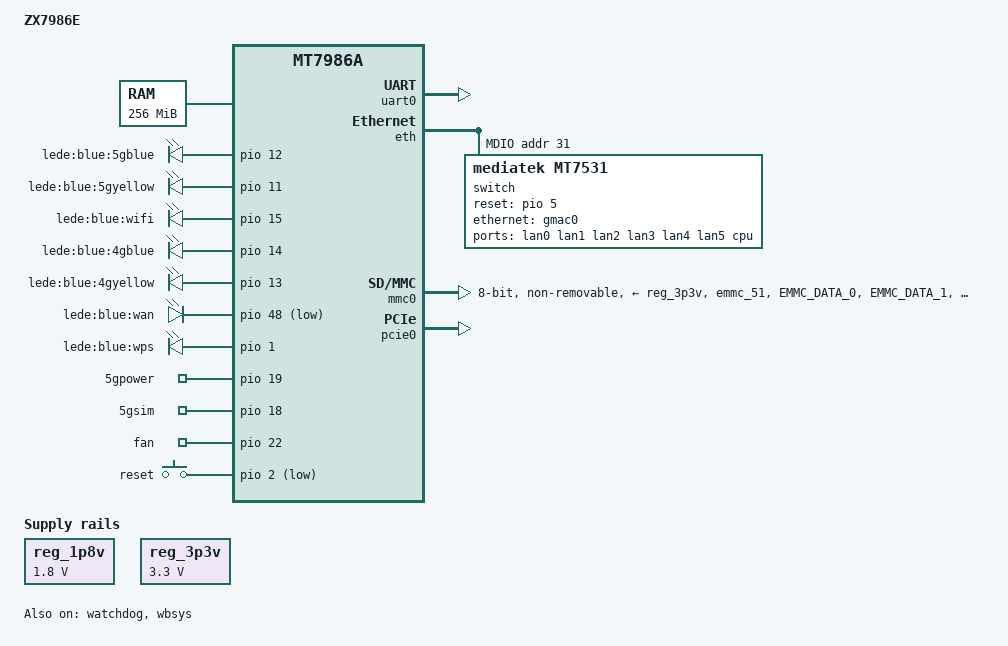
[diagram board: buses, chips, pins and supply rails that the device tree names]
/dts-v1/;
#include "mt7986a.dtsi"
#include "mt7986a-pinctrl.dtsi"
#include <dt-bindings/input/input.h>

/ {
	model = "ZX7986E";
	compatible = "ZX7986E";
	chosen {
		bootargs = "console=ttyS0,115200n1 loglevel=8  \
				earlycon=uart8250,mmio32,0x11002000 \
				root=PARTLABEL=rootfs rootwait rootfstype=squashfs,f2fs";
	};

	memory {
		reg = <0 0x40000000 0 0x10000000>;
	};

	gpio-leds {
		compatible = "gpio-leds";

		5gblue {
			label = "lede:blue:5gblue";
			gpios = <&pio 12 0>;
			linux,default-trigger = "none";
			default-state = "off";
		};

		5gyellow {
			label = "lede:blue:5gyellow";
			gpios = <&pio 11 0>;
			linux,default-trigger = "none";
			default-state = "off";
		};

		wifi {
			label = "lede:blue:wifi";
			gpios = <&pio 15 0>;
			linux,default-trigger = "none";
			default-state = "off";
		};

		4gblue {
			label = "lede:blue:4gblue";
			gpios = <&pio 14 0>;
			linux,default-trigger = "none";
			default-state = "off";
		};

		4gyellow {
			label = "lede:blue:4gyellow";
			gpios = <&pio 13 0>;
			linux,default-trigger = "none";
			default-state = "off";
		};

		wan {
			label = "lede:blue:wan";
			gpios = <&pio 48 1>;
			linux,default-trigger = "none";
			default-state = "off";
		};

		wps {
			label = "lede:blue:wps";
			gpios = <&pio 1 0>;
			linux,default-trigger = "none";
			default-state = "off";
		};
	};

	gpio-export {
		compatible = "gpio-export";
		5gpower {
			gpio-export,name = "5gpower";
			gpio-export,output = <0>; // OUT_INIT_LOW
			gpios = <&pio 19 0>;    // GPIO 19, ACTIVE_LOW
		};

		5gsim {
			gpio-export,name = "5gsim";
			gpio-export,output = <1>; // OUT_INIT_LOW
			gpios = <&pio 18 0>;    // GPIO 18, ACTIVE_LOW
		};

		fan {
			gpio-export,name = "fan";
			gpio-export,output = <1>; // OUT_INIT_LOW
			gpios = <&pio 22 0>;    // GPIO 22, ACTIVE_LOW
		};
	};

	gpio-keys {
		compatible = "gpio-keys";
		#address-cells = <1>;
		#size-cells = <0>;
		poll-interval = <20>;

		reset {
			label = "reset";
			gpios = <&pio 2 1>;
			linux,code = <KEY_RESTART>;
		};
	};

	reg_1p8v: regulator-1p8v {
		compatible = "regulator-fixed";
		regulator-name = "fixed-1.8V";
		regulator-min-microvolt = <1800000>;
		regulator-max-microvolt = <1800000>;
		regulator-boot-on;
		regulator-always-on;
	};

	reg_3p3v: regulator-3p3v {
		compatible = "regulator-fixed";
		regulator-name = "fixed-3.3V";
		regulator-min-microvolt = <3300000>;
		regulator-max-microvolt = <3300000>;
		regulator-boot-on;
		regulator-always-on;
	};

};

/*&pwm {
	pinctrl-names = "default";
	pinctrl-0 = <&pwm0_pin &pwm1_pin_g1>;
	status = "disabled";
};*/

&uart0 {
	status = "okay";
};

&watchdog {
	status = "okay";
};

&eth {
	status = "okay";

	gmac0: mac@0 {
		compatible = "mediatek,eth-mac";
		reg = <0>;
		phy-mode = "2500base-x";

		fixed-link {
			speed = <2500>;
			full-duplex;
			pause;
		};
	};

	gmac1: mac@1 {
		compatible = "mediatek,eth-mac";
		reg = <1>;
		phy-mode = "2500base-x";

		fixed-link {
			speed = <2500>;
			full-duplex;
			pause;
		};
	};

	mdio: mdio-bus {
		#address-cells = <1>;
		#size-cells = <0>;

		reset-gpios = <&pio 6 1>;
		reset-delay-us = <600>;

		switch@0 {
			compatible = "mediatek,mt7531";
			reg = <31>;
			reset-gpios = <&pio 5 0>;

			ports {
				#address-cells = <1>;
				#size-cells = <0>;

				port@0 {
					reg = <0>;
					label = "lan0";
				};

				port@1 {
					reg = <1>;
					label = "lan1";
				};

				port@2 {
					reg = <2>;
					label = "lan2";
				};

				port@3 {
					reg = <3>;
					label = "lan3";
				};

				port@4 {
					reg = <4>;
					label = "lan4";
				};

				port@5 {
                	reg = <5>;
                    label = "lan5";
                    phy-mode = "2500base-x";
	                fixed-link {
        	                speed = <2500>;
                	        full-duplex;
                        	pause;
                    };
				};

				port@6 {
					reg = <6>;
					label = "cpu";
					ethernet = <&gmac0>;
					phy-mode = "2500base-x";

					fixed-link {
						speed = <2500>;
						full-duplex;
						pause;
					};
				};
			};
		};
	};
};

&hnat {
	mtketh-wan = "eth1";
	mtketh-lan = "lan";
	mtketh-max-gmac = <2>;
	status = "disabled";
};

&mmc0 {
	pinctrl-names = "default", "state_uhs";
	pinctrl-0 = <&mmc0_pins_default>;
	pinctrl-1 = <&mmc0_pins_uhs>;
	bus-width = <8>;
	max-frequency = <200000000>;
	cap-mmc-highspeed;
	mmc-hs200-1_8v;
	mmc-hs400-1_8v;
	hs400-ds-delay = <0x14014>;
	vmmc-supply = <&reg_3p3v>;
	vqmmc-supply = <&reg_1p8v>;
	non-removable;
	no-sd;
	no-sdio;
	status = "okay";
};

&pcie0 {
	pinctrl-names = "default";
	pinctrl-0 = <&pcie0_pins>;
	status = "okay";
};

&wbsys {
	status = "okay";
	pinctrl-names = "default", "dbdc";
	pinctrl-0 = <&wf_2g_5g_pins>;
	pinctrl-1 = <&wf_dbdc_pins>;
};

&pio {
	mmc0_pins_default: mmc0-pins-50-to-61-default {
		mux {
			function = "flash";
			groups = "emmc_51";
		};
		conf-cmd-dat {
			pins = "EMMC_DATA_0", "EMMC_DATA_1", "EMMC_DATA_2",
			       "EMMC_DATA_3", "EMMC_DATA_4", "EMMC_DATA_5",
			       "EMMC_DATA_6", "EMMC_DATA_7", "EMMC_CMD";
			input-enable;
			drive-strength = <MTK_DRIVE_4mA>;
			mediatek,pull-up-adv = <1>;	/* pull-up 10K */
		};
		conf-clk {
			pins = "EMMC_CK";
			drive-strength = <MTK_DRIVE_6mA>;
			mediatek,pull-down-adv = <2>;	/* pull-down 50K */
		};
		conf-ds {
			pins = "EMMC_DSL";
			mediatek,pull-down-adv = <2>;	/* pull-down 50K */
		};
		conf-rst {
			pins = "EMMC_RSTB";
			drive-strength = <MTK_DRIVE_4mA>;
			mediatek,pull-up-adv = <1>;	/* pull-up 10K */
		};
	};

	mmc0_pins_uhs: mmc0-pins-50-to-61-uhs {
		mux {
			function = "flash";
			groups = "emmc_51";
		};
		conf-cmd-dat {
			pins = "EMMC_DATA_0", "EMMC_DATA_1", "EMMC_DATA_2",
			       "EMMC_DATA_3", "EMMC_DATA_4", "EMMC_DATA_5",
			       "EMMC_DATA_6", "EMMC_DATA_7", "EMMC_CMD";
			input-enable;
			drive-strength = <MTK_DRIVE_4mA>;
			mediatek,pull-up-adv = <1>;	/* pull-up 10K */
		};
		conf-clk {
			pins = "EMMC_CK";
			drive-strength = <MTK_DRIVE_6mA>;
			mediatek,pull-down-adv = <2>;	/* pull-down 50K */
		};
		conf-ds {
			pins = "EMMC_DSL";
			mediatek,pull-down-adv = <2>;	/* pull-down 50K */
		};
		conf-rst {
			pins = "EMMC_RSTB";
			drive-strength = <MTK_DRIVE_4mA>;
			mediatek,pull-up-adv = <1>;	/* pull-up 10K */
		};
	};

	wf_2g_5g_pins: wf_2g_5g-pins {
		mux {
			function = "wifi";
			groups = "wf_2g", "wf_5g";
		};
		conf {
			pins = "WF0_HB1", "WF0_HB2", "WF0_HB3", "WF0_HB4",
			       "WF0_HB0", "WF0_HB0_B", "WF0_HB5", "WF0_HB6",
			       "WF0_HB7", "WF0_HB8", "WF0_HB9", "WF0_HB10",
			       "WF0_TOP_CLK", "WF0_TOP_DATA", "WF1_HB1",
			       "WF1_HB2", "WF1_HB3", "WF1_HB4", "WF1_HB0",
			       "WF1_HB5", "WF1_HB6", "WF1_HB7", "WF1_HB8",
			       "WF1_TOP_CLK", "WF1_TOP_DATA";
			drive-strength = <MTK_DRIVE_4mA>;
		};
	};

	wf_dbdc_pins: wf_dbdc-pins {
		mux {
			function = "wifi";
			groups = "wf_dbdc";
		};
		conf {
			pins = "WF0_HB1", "WF0_HB2", "WF0_HB3", "WF0_HB4",
			       "WF0_HB0", "WF0_HB0_B", "WF0_HB5", "WF0_HB6",
			       "WF0_HB7", "WF0_HB8", "WF0_HB9", "WF0_HB10",
			       "WF0_TOP_CLK", "WF0_TOP_DATA", "WF1_HB1",
			       "WF1_HB2", "WF1_HB3", "WF1_HB4", "WF1_HB0",
			       "WF1_HB5", "WF1_HB6", "WF1_HB7", "WF1_HB8",
			       "WF1_TOP_CLK", "WF1_TOP_DATA";
			drive-strength = <MTK_DRIVE_4mA>;
		};
	};
};
